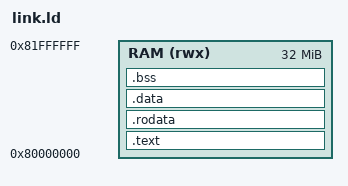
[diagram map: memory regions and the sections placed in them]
OUTPUT_ARCH(riscv)
ENTRY(_start)

MEMORY
{
    RAM (rwx) : ORIGIN = 0x80000000, LENGTH = 32M
}

SECTIONS
{
    .text : { *(.text*) } > RAM
    .rodata : { *(.rodata*) } > RAM
    .data : { *(.data*) } > RAM

    .bss : {
        _sbss = .;
        *(.bss*)
        *(COMMON)
        _ebss = .;
    } > RAM
}
